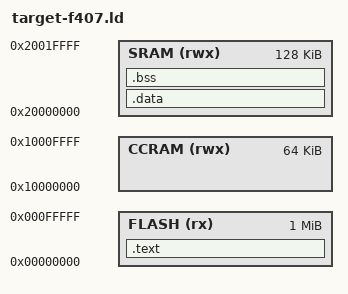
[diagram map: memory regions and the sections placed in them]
/*
 *
 * Embedded System Architecture - Second Edition
 * Copyright (c) 2018-2022 Packt
 *
 * Author: Daniele Lacamera <root@danielinux.net>
 *
 * MIT License
 * Permission is hereby granted, free of charge, to any person obtaining a copy
 * of this software and associated documentation files (the "Software"), to deal 
 * in the Software without restriction, including without limitation the rights
 * to use, copy, modify, merge, publish, distribute, sublicense, and/or sell
 * copies of the Software, and to permit persons to whom the Software is
 * furnished to do so, subject to the following conditions:
 * 
 * The above copyright notice and this permission notice shall be included in all
 * copies or substantial portions of the Software.
 * 
 * THE SOFTWARE IS PROVIDED "AS IS", WITHOUT WARRANTY OF ANY KIND, EXPRESS OR
 * IMPLIED, INCLUDING BUT NOT LIMITED TO THE WARRANTIES OF MERCHANTABILITY,
 * FITNESS FOR A PARTICULAR PURPOSE AND NONINFRINGEMENT. IN NO EVENT SHALL THE
 * AUTHORS OR COPYRIGHT HOLDERS BE LIABLE FOR ANY CLAIM, DAMAGES OR OTHER
 * LIABILITY, WHETHER IN AN ACTION OF CONTRACT, TORT OR OTHERWISE, ARISING FROM, 
 * OUT OF OR IN CONNECTION WITH THE SOFTWARE OR THE USE OR OTHER DEALINGS IN THE 
 * SOFTWARE.
 */
MEMORY
{
    FLASH (rx) : ORIGIN = 0x00000000, LENGTH = 1M
    SRAM (rwx) : ORIGIN = 0x20000000, LENGTH = 128K
    CCRAM(rwx) : ORIGIN = 0x10000000, LENGTH = 64K
}

SECTIONS
{
    .text :
    {
        _start_text = .;
        KEEP(*(.isr_vector))
        *(.text*)
        *(.rodata*)
        . = ALIGN(4);
        _end_text = .;
    } > FLASH

    _stored_data = .;

    .data : AT (_stored_data)
    {
        _start_data = .;
        *(.data*)
        . = ALIGN(4);
        _end_data = .;
    } > SRAM

    .bss :
    {
        _start_bss = .;
        *(.bss*)
        *(COMMON)
        . = ALIGN(4);
        _end_bss = .;
        _end = .;
    } > SRAM

}

PROVIDE(_stack_size = (16 * 1024));
PROVIDE(_end_stack = ORIGIN(CCRAM) + _stack_size);
